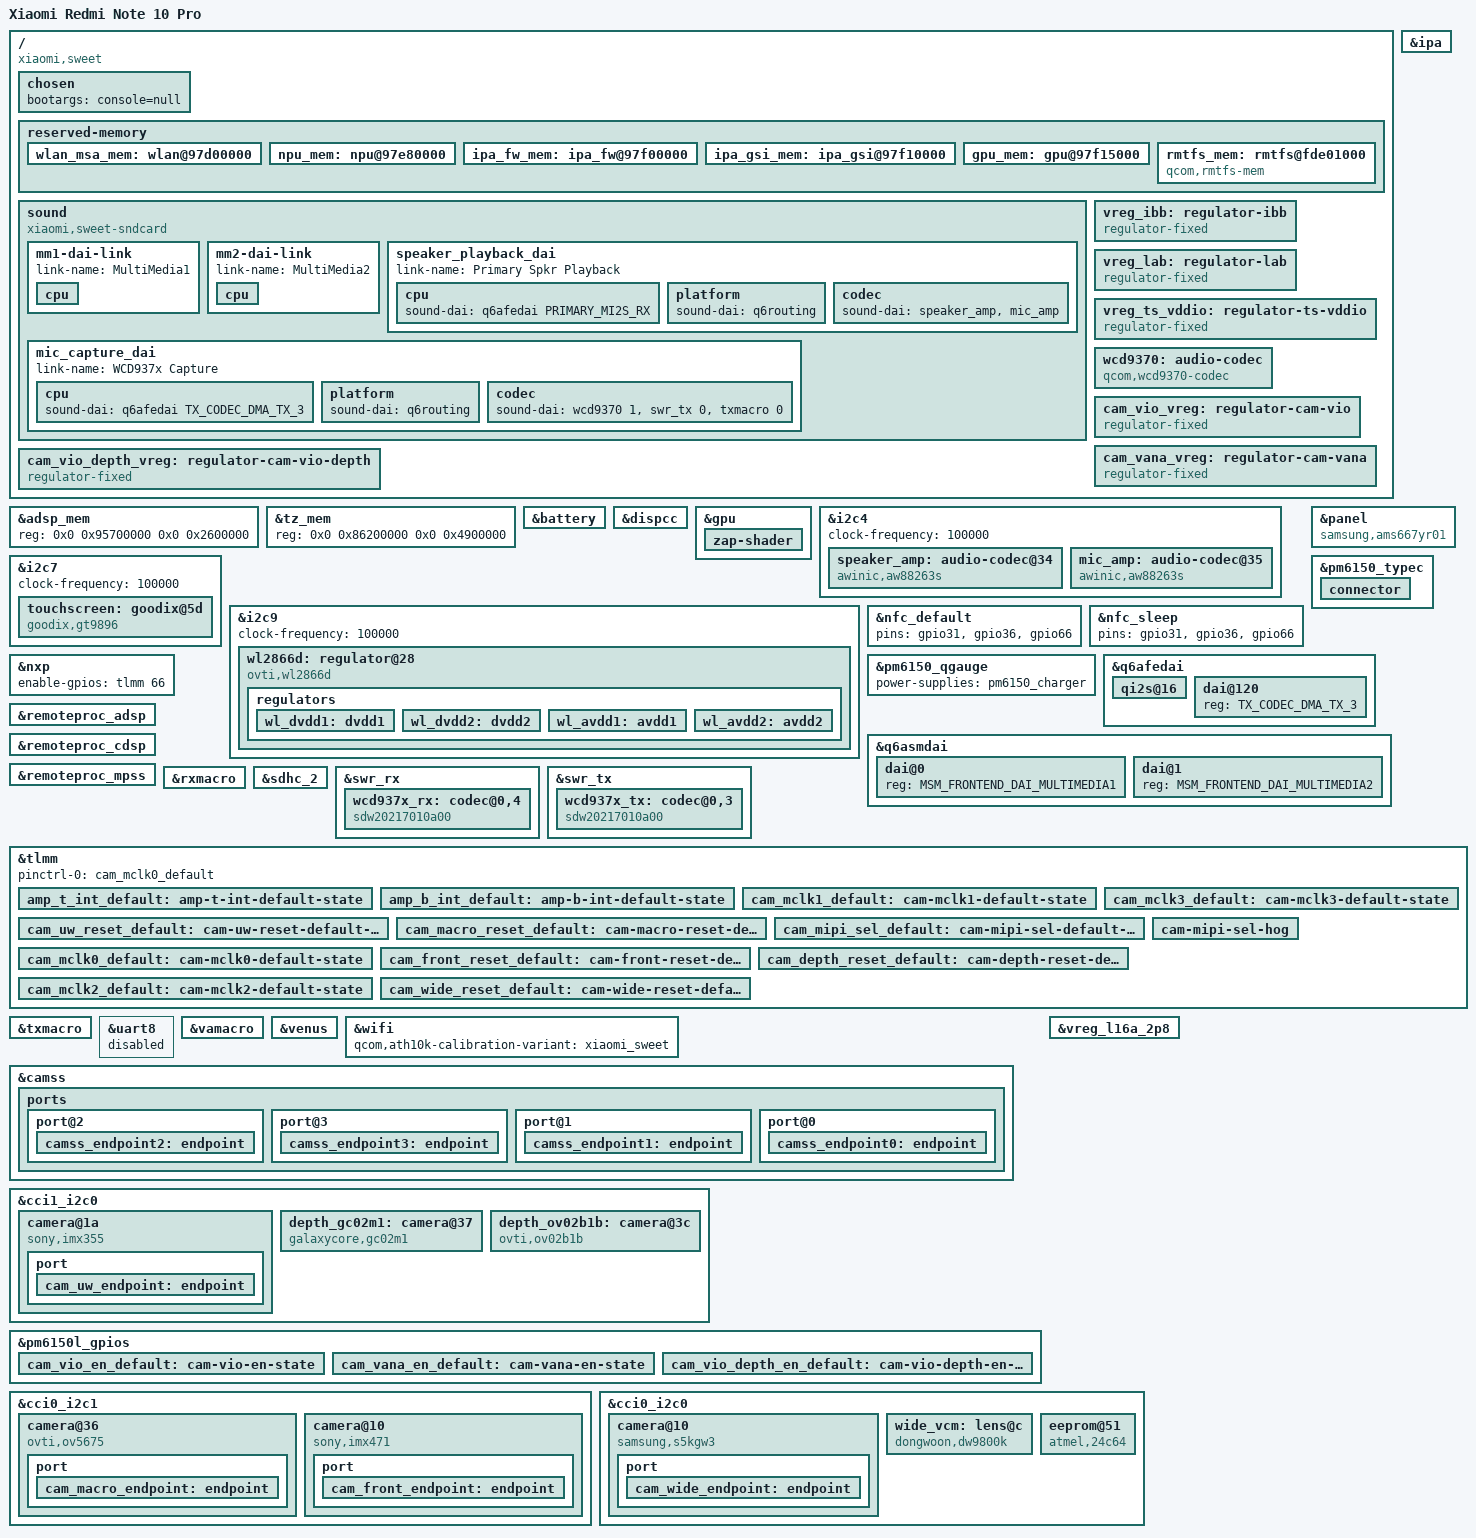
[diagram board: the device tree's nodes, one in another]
// SPDX-License-Identifier: BSD-3-Clause
/*
 * Copyright (c) 2024, Danila Tikhonov <danila@jiaxyga.com>
 * Copyright (c) 2024, Kali Prasad <kprasadvnsi@protonmail.com>
 * Copyright (c) 2024, Salvatore Stella <salvatore.stella@univaq.it>
 */

/dts-v1/;

#include "sm7150-xiaomi-common.dtsi"

/delete-node/ &wlan_msa_mem;
/delete-node/ &npu_mem;
/delete-node/ &ipa_fw_mem;
/delete-node/ &ipa_gsi_mem;
/delete-node/ &gpu_mem;

&adsp_mem {
	reg = <0x0 0x95700000 0x0 0x2600000>;
};

&tz_mem {
	reg = <0x0 0x86200000 0x0 0x4900000>;
};

/ {
	model = "Xiaomi Redmi Note 10 Pro";
	compatible = "xiaomi,sweet", "qcom,sm7150";

	qcom,board-id = <46 0>;

	chosen {
		/*
		 * Serial engine with the debug UART operates in SPI mode on sweet
		 * So disable console and remove stdout-path
		 */
		/delete-property/ stdout-path;
		bootargs = "console=null";
	};

	reserved-memory {
		wlan_msa_mem: wlan@97d00000 {
			reg = <0x0 0x97d00000 0x0 0x180000>;
			no-map;
		};

		npu_mem: npu@97e80000 {
			reg = <0x0 0x97e80000 0x0 0x80000>;
			no-map;
		};

		ipa_fw_mem: ipa_fw@97f00000 {
			reg = <0x0 0x97f00000 0x0 0x10000>;
			no-map;
		};

		ipa_gsi_mem: ipa_gsi@97f10000 {
			reg = <0x0 0x97f10000 0x0 0x5000>;
			no-map;
		};

		gpu_mem: gpu@97f15000 {
			reg = <0x0 0x97f15000 0x0 0x2000>;
			no-map;
		};

		rmtfs_mem: rmtfs@fde01000 {
			compatible = "qcom,rmtfs-mem";
			reg = <0 0xfde01000 0 0x200000>;
			no-map;

			qcom,client-id = <1>;
			qcom,vmid = <QCOM_SCM_VMID_MSS_MSA>;
		};
	};

	sound {
		compatible = "xiaomi,sweet-sndcard";
		pinctrl-0 = <&pri_mi2s_active &pri_mi2s_ws_active>;
		pinctrl-names = "default";
		model = "Redmi Note 10 Pro";
		widgets = "Speaker", "Speaker Spk",
			  "Speaker", "Microphone Spk";
		audio-routing = "Speaker Spk", "Speaker DAC Output",
				"Microphone Spk", "Microphone DAC Output",
				"Speaker AIF_RX", "PRI_MI2S_RX",
				"Microphone AIF_RX", "PRI_MI2S_RX",
				"AMIC1", "MIC BIAS1",
				"AMIC2", "MIC BIAS2",
				"AMIC3", "MIC BIAS3",
				"TX SWR_ADC0", "ADC1_OUTPUT";

		mm1-dai-link {
			link-name = "MultiMedia1";
			cpu {
				sound-dai = <&q6asmdai MSM_FRONTEND_DAI_MULTIMEDIA1>;
			};
		};

		mm2-dai-link {
			link-name = "MultiMedia2";
			cpu {
				sound-dai = <&q6asmdai MSM_FRONTEND_DAI_MULTIMEDIA2>;
			};
		};

		speaker_playback_dai {
			link-name = "Primary Spkr Playback";
			cpu {
				sound-dai = <&q6afedai PRIMARY_MI2S_RX>;
			};

			platform {
				sound-dai = <&q6routing>;
			};

			codec {
				sound-dai = <&speaker_amp>, <&mic_amp>;
			};
		};

		mic_capture_dai {
			link-name = "WCD937x Capture";
			cpu {
				sound-dai = <&q6afedai TX_CODEC_DMA_TX_3>;
			};

			platform {
				sound-dai = <&q6routing>;
			};

			codec {
				sound-dai = <&wcd9370 1>, <&swr_tx 0>, <&txmacro 0>;
			};
		};
	};

	vreg_ibb: regulator-ibb {
		compatible = "regulator-fixed";
		regulator-name = "ibb";
		regulator-min-microvolt = <6000000>;
		regulator-max-microvolt = <6000000>;
	};

	vreg_lab: regulator-lab {
		compatible = "regulator-fixed";
		regulator-name = "lab";
		regulator-min-microvolt = <6000000>;
		regulator-max-microvolt = <6000000>;
	};

	vreg_ts_vddio: regulator-ts-vddio {
		compatible = "regulator-fixed";
		regulator-name = "vreg_ts_vddio";
		regulator-min-microvolt = <1800000>;
		regulator-max-microvolt = <1800000>;
		gpio = <&tlmm 90 GPIO_ACTIVE_HIGH>;
		enable-active-high;
		regulator-boot-on;
		startup-delay-us = <4000>;
	};

	wcd9370: audio-codec {
		compatible = "qcom,wcd9370-codec";
		pinctrl-0 = <&wcd9375_reset_active>;
		pinctrl-names = "default";

		reset-gpios = <&lpass_tlmm 6 GPIO_ACTIVE_LOW>;

		vdd-buck-supply = <&vreg_l15a_1p8>;
		vdd-rxtx-supply = <&vreg_l10a_1p8>;
		vdd-px-supply = <&vreg_l10a_1p8>;
		vdd-mic-bias-supply = <&vreg_bob>;

		qcom,micbias1-microvolt = <2750000>;
		qcom,micbias2-microvolt = <2750000>;
		qcom,micbias3-microvolt = <2750000>;
		qcom,mbhc-buttons-vthreshold-microvolt = <75000 150000 237000 500000
							  500000 500000 500000 500000>;

		qcom,rx-device = <&wcd937x_rx>;
		qcom,tx-device = <&wcd937x_tx>;

		#sound-dai-cells = <1>;
	};
};

&battery {
	charge-full-design-microamp-hours = <5020000>;
	/* Also the DCP input current limit of the charger, AICL backs off on weak adapters */
	constant-charge-current-max-microamp = <2000000>;
	/* K6 Sunwoda 5020 mAh profile from the downstream qpnp-qg battery data, 25 degC */
	factory-internal-resistance-micro-ohms = <200000>;
	ocv-capacity-celsius = <25>;
	ocv-capacity-table-0 = <4433500 100>, <4416800 98>, <4399000 96>, <4380200 94>,
		<4360400 92>, <4339300 90>, <4316400 88>, <4292500 86>,
		<4268400 84>, <4243800 82>, <4219400 80>, <4195100 78>,
		<4171300 76>, <4148000 74>, <4125300 72>, <4103300 70>,
		<4081900 68>, <4061100 66>, <4041400 64>, <4023000 62>,
		<4002100 60>, <3973100 58>, <3943500 56>, <3924400 54>,
		<3910600 52>, <3898200 50>, <3886500 48>, <3875600 46>,
		<3865200 44>, <3855100 42>, <3845900 40>, <3837700 38>,
		<3830200 36>, <3823400 34>, <3817200 32>, <3811500 30>,
		<3806300 28>, <3801100 26>, <3793700 24>, <3783300 22>,
		<3771500 20>, <3758600 18>, <3744500 16>, <3728000 14>,
		<3715300 12>, <3707800 10>, <3705700 9>, <3704200 8>,
		<3701200 7>, <3688500 6>, <3652500 5>, <3604600 4>,
		<3542800 3>, <3458300 2>, <3325600 1>, <3000000 0>;
};

&dispcc {
	status = "okay";
};

&gpu {
	zap-shader {
		firmware-name = "qcom/sm7150/xiaomi/sweet/a615_zap.mbn";
	};
};

&i2c4 {
	clock-frequency = <100000>;
	status = "okay";

	/* Speaker */
        speaker_amp: audio-codec@34 {
		compatible = "awinic,aw88263s";
		reg = <0x34>;

		reset-gpios = <&tlmm 64 GPIO_ACTIVE_HIGH>;
		irq-gpio = <&tlmm 93 GPIO_ACTIVE_HIGH>;

		pinctrl-names = "default";
		pinctrl-0 = <&amp_t_int_default>;

		awinic,audio-channel = <0>;

		sound-name-prefix = "Speaker";
		#sound-dai-cells = <0>;
        };

	/* Microphone */
	mic_amp: audio-codec@35 {
		compatible = "awinic,aw88263s";
		reg = <0x35>;

		reset-gpios = <&tlmm 72 GPIO_ACTIVE_HIGH>;
		irq-gpio = <&tlmm 56 GPIO_ACTIVE_HIGH>;

		pinctrl-names = "default";
		pinctrl-0 = <&amp_b_int_default>;

		awinic,audio-channel = <1>;

		sound-name-prefix = "Microphone";
		#sound-dai-cells = <0>;
        };
};

&i2c7 {
	clock-frequency = <100000>;
	status = "okay";

	touchscreen: goodix@5d {
		compatible = "goodix,gt9896";
		reg = <0x5d>;
		interrupts-extended = <&tlmm 9 IRQ_TYPE_LEVEL_LOW>;
		reset-gpios = <&tlmm 8 GPIO_ACTIVE_LOW>;
		avdd-supply = <&vreg_l11c_3p3>;
		vddio-supply = <&vreg_ts_vddio>;
		panel = <&panel>;
		touchscreen-size-x = <1080>;
		touchscreen-size-y = <2400>;
	};
};

&i2c9 {
	clock-frequency = <100000>;
	status = "okay";

	wl2866d: regulator@28 {
		compatible = "ovti,wl2866d";
		reg = <0x28>;

		enable-gpios = <&tlmm 30 GPIO_ACTIVE_HIGH>;
		vin1-supply = <&vreg_s8c_1p35>;
		vin2-supply = <&vreg_bob>;

		regulators {
			wl_dvdd1: dvdd1 {
				regulator-name = "wl_dvdd1";
				regulator-min-microvolt = <1200000>;
				regulator-max-microvolt = <1200000>;
			};

			wl_dvdd2: dvdd2 {
				regulator-name = "wl_dvdd2";
				regulator-min-microvolt = <1050000>;
				regulator-max-microvolt = <1050000>;
			};

			wl_avdd1: avdd1 {
				regulator-name = "wl_avdd1";
				regulator-min-microvolt = <2800000>;
				regulator-max-microvolt = <2800000>;
			};

			wl_avdd2: avdd2 {
				regulator-name = "wl_avdd2";
				regulator-min-microvolt = <2700000>;
				regulator-max-microvolt = <2700000>;
			};
		};
	};

	/* lionsemi,ln8000 (charger) @ 51 */
	/* awinic,aw8624 (haptics) @ 5a */
	/* ti,bq2597x (charger) @ 66 */
};

&ipa {
	firmware-name = "qcom/sm7150/xiaomi/sweet/ipa_fws.mbn";
};

&nfc_default {
	pins = "gpio31", "gpio36", "gpio66";
};

&nfc_sleep {
	pins = "gpio31", "gpio36", "gpio66";
};

&nxp {
	enable-gpios = <&tlmm 66 GPIO_ACTIVE_HIGH>;
};

&panel {
	compatible = "samsung,ams667yr01";

	vsn-supply = <&vreg_ibb>;
	vsp-supply = <&vreg_lab>;
};

&pm6150_qgauge {
	power-supplies = <&pm6150_charger>;
};

&pm6150_typec {
	connector {
		op-sink-microwatt = <15000000>;
		power-role = "dual";

		sink-pdos = <PDO_FIXED(5000, 3000, PDO_FIXED_DUAL_ROLE |
			     PDO_FIXED_USB_COMM | PDO_FIXED_DATA_SWAP)>;
	};
};

&q6afedai {
	qi2s@16 {
		reg = <PRIMARY_MI2S_RX>;
		qcom,sd-lines = <0>;
	};

	dai@120 {
		reg = <TX_CODEC_DMA_TX_3>;
	};
};

&q6asmdai {
	dai@0 {
		reg = <MSM_FRONTEND_DAI_MULTIMEDIA1>;
	};

	dai@1 {
		reg = <MSM_FRONTEND_DAI_MULTIMEDIA2>;
	};
};

&remoteproc_adsp {
	firmware-name = "qcom/sm7150/xiaomi/sweet/adsp.mbn";
};

&remoteproc_cdsp {
	firmware-name = "qcom/sm7150/xiaomi/sweet/cdsp.mbn";
};

&remoteproc_mpss {
	firmware-name = "qcom/sm7150/xiaomi/sweet/modem.mbn";
};

&rxmacro {
	status = "okay";
};

&sdhc_2 {
	status = "okay";
};

&swr_rx {
	status = "okay";

	wcd937x_rx: codec@0,4 {
		compatible = "sdw20217010a00";
		reg = <0 4>;
		qcom,rx-port-mapping = <1 2 3 4 5>;
		qcom,rx-channel-mapping = /bits/ 8 <1 2 1 1 2 1 1 2>;
		#sound-dai-cells = <1>;
	};
};

&swr_tx {
	status = "okay";

	wcd937x_tx: codec@0,3 {
		compatible = "sdw20217010a00";
		reg = <0 3>;
		qcom,tx-port-mapping = <2 3 4 5>;
		qcom,tx-channel-mapping = /bits/ 8 <1 1 2 1 2 3 3 4 1 2 3 4>;
		#sound-dai-cells = <1>;
	};
};

&tlmm {
	amp_t_int_default: amp-t-int-default-state {
		pins = "gpio93";
		function = "gpio";
		drive-strength = <2>;
		bias-pull-up;
		input-enable;
	};

	amp_b_int_default: amp-b-int-default-state {
		pins = "gpio56";
		function = "gpio";
		drive-strength = <2>;
		bias-pull-up;
		input-enable;
	};
};

&txmacro {
	status = "okay";
};

&uart8 {
	status = "disabled";
};

&vamacro {
	status = "okay";
};

&venus {
	firmware-name = "qcom/sm7150/xiaomi/sweet/venus.mbn";
};

&wifi {
	qcom,ath10k-calibration-variant = "xiaomi_sweet";
};

/ {
	/* DOVDD 1.8 V for the cameras: pm6150l gpio4 */
	cam_vio_vreg: regulator-cam-vio {
		compatible = "regulator-fixed";
		regulator-name = "cam_vio";
		regulator-min-microvolt = <1800000>;
		regulator-max-microvolt = <1800000>;
		regulator-enable-ramp-delay = <100>;
		gpio = <&pm6150l_gpios 4 GPIO_ACTIVE_HIGH>;
		enable-active-high;
		vin-supply = <&vreg_s5a_2p0>;
		pinctrl-0 = <&cam_vio_en_default>;
		pinctrl-names = "default";
	};
};

&camss {
	ports {
		port@2 {
			camss_endpoint2: endpoint {
				data-lanes = <0 1 2 3>;
				remote-endpoint = <&cam_uw_endpoint>;
			};
		};
	};
};

/* 8 MP ultra-wide camera */
&cci1_i2c0 {
	camera@1a {
		compatible = "sony,imx355";
		reg = <0x1a>;

		clocks = <&camcc CAMCC_MCLK1_CLK>;
		assigned-clocks = <&camcc CAMCC_MCLK1_CLK>;
		assigned-clock-rates = <19200000>;

		reset-gpios = <&tlmm 25 GPIO_ACTIVE_LOW>;

		avdd-supply = <&wl_avdd2>;
		dvdd-supply = <&wl_dvdd1>;
		dovdd-supply = <&cam_vio_vreg>;

		pinctrl-0 = <&cam_mclk1_default &cam_uw_reset_default>;
		pinctrl-names = "default";

		orientation = <1>;
		rotation = <90>;

		port {
			cam_uw_endpoint: endpoint {
				data-lanes = <1 2 3 4>;
				link-frequencies = /bits/ 64 <360000000>;
				remote-endpoint = <&camss_endpoint2>;
			};
		};
	};
};

&pm6150l_gpios {
	cam_vio_en_default: cam-vio-en-state {
		pins = "gpio4";
		function = PMIC_GPIO_FUNC_NORMAL;
		power-source = <0>;
	};
};

&tlmm {
	cam_mclk1_default: cam-mclk1-default-state {
		pins = "gpio14";
		function = "cam_mclk";
		drive-strength = <4>;
		bias-disable;
	};

	cam_uw_reset_default: cam-uw-reset-default-state {
		pins = "gpio25";
		function = "gpio";
		drive-strength = <2>;
		bias-disable;
	};
};

/ {
	/*
	 * AVDD 2.8 V for the macro (OV5675) and depth cameras: pm6150l gpio11,
	 * vin BOB (downstream camera_d_vdda_regulator, "cam_vana")
	 */
	cam_vana_vreg: regulator-cam-vana {
		compatible = "regulator-fixed";
		regulator-name = "cam_vana";
		regulator-min-microvolt = <2800000>;
		regulator-max-microvolt = <2800000>;
		regulator-enable-ramp-delay = <100>;
		gpio = <&pm6150l_gpios 11 GPIO_ACTIVE_HIGH>;
		enable-active-high;
		vin-supply = <&vreg_bob>;
		pinctrl-0 = <&cam_vana_en_default>;
		pinctrl-names = "default";
	};
};

&camss {
	ports {
		port@3 {
			camss_endpoint3: endpoint {
				data-lanes = <0 1>;
				bus-type = <4>; /* MEDIA_BUS_TYPE_CSI2_DPHY */
				remote-endpoint = <&cam_macro_endpoint>;
			};
		};
	};
};

/* 5 MP macro camera, shares CSIPHY3 with the depth camera via a MIPI switch */
&cci0_i2c1 {
	camera@36 {
		compatible = "ovti,ov5675";
		reg = <0x36>;

		clocks = <&camcc CAMCC_MCLK3_CLK>;
		assigned-clocks = <&camcc CAMCC_MCLK3_CLK>;
		assigned-clock-rates = <19200000>;

		reset-gpios = <&tlmm 24 GPIO_ACTIVE_LOW>;

		avdd-supply = <&cam_vana_vreg>;
		dvdd-supply = <&wl_dvdd1>;
		dovdd-supply = <&cam_vio_vreg>;

		pinctrl-0 = <&cam_mclk3_default &cam_macro_reset_default
			     &cam_mipi_sel_default>;
		pinctrl-names = "default";

		orientation = <1>;
		rotation = <90>;

		port {
			cam_macro_endpoint: endpoint {
				data-lanes = <1 2>;
				link-frequencies = /bits/ 64 <450000000>;
				remote-endpoint = <&camss_endpoint3>;
			};
		};
	};
};

&pm6150l_gpios {
	cam_vana_en_default: cam-vana-en-state {
		pins = "gpio11";
		function = PMIC_GPIO_FUNC_NORMAL;
		power-source = <0>;
	};
};

&tlmm {
	cam_mclk3_default: cam-mclk3-default-state {
		pins = "gpio16";
		function = "cam_mclk";
		drive-strength = <4>;
		bias-disable;
	};

	cam_macro_reset_default: cam-macro-reset-default-state {
		pins = "gpio24";
		function = "gpio";
		drive-strength = <2>;
		bias-disable;
	};

	cam_mipi_sel_default: cam-mipi-sel-default-state {
		pins = "gpio88";
		function = "gpio";
		drive-strength = <2>;
		bias-disable;
	};

	/*
	 * MIPI switch select for CSIPHY3 (downstream gpio-custom1 = tlmm 88,
	 * CamX power-up sequence drives it HIGH for the macro, LOW for depth).
	 * No mainline driver for the depth sensor, so pin it to the macro.
	 */
	cam-mipi-sel-hog {
		gpio-hog;
		gpios = <88 GPIO_ACTIVE_HIGH>;
		output-high;
		line-name = "cam-mipi-sel-macro";
	};
};

&camss {
	ports {
		port@1 {
			camss_endpoint1: endpoint {
				data-lanes = <0 1 2 3>;
				remote-endpoint = <&cam_front_endpoint>;
			};
		};
	};
};

/* 16 MP front camera, Sony IMX471 */
&cci0_i2c1 {
	camera@10 {
		compatible = "sony,imx471";
		reg = <0x10>;

		clocks = <&camcc CAMCC_MCLK0_CLK>;
		assigned-clocks = <&camcc CAMCC_MCLK0_CLK>;
		assigned-clock-rates = <19200000>;

		reset-gpios = <&tlmm 23 GPIO_ACTIVE_LOW>;

		avdd-supply = <&cam_vana_vreg>;
		dvdd-supply = <&wl_dvdd2>;
		dovdd-supply = <&cam_vio_vreg>;

		/*
		 * MCLK0 (gpio13) is shared with the depth camera on cci1_i2c0;
		 * cam_mclk0_default is applied as a tlmm hog (see &tlmm below).
		 */
		pinctrl-0 = <&cam_front_reset_default>;
		pinctrl-names = "default";

		orientation = <0>;
		/*
		 * Android reports roll 270 with the sensor read out H+V flipped
		 * (init table 0x0101 = 0x03); this driver defaults to no flip,
		 * so the mounting rotation is 270 - 180 = 90.
		 */
		rotation = <90>;

		port {
			cam_front_endpoint: endpoint {
				data-lanes = <1 2 3 4>;
				link-frequencies = /bits/ 64 <164800000>;
				remote-endpoint = <&camss_endpoint1>;
			};
		};
	};
};

&tlmm {
	cam_mclk0_default: cam-mclk0-default-state {
		pins = "gpio13";
		function = "cam_mclk";
		drive-strength = <4>;
		bias-disable;
	};

	cam_front_reset_default: cam-front-reset-default-state {
		pins = "gpio23";
		function = "gpio";
		drive-strength = <2>;
		bias-disable;
	};
};

/ {
	/*
	 * DOVDD 1.8 V for the depth camera: pm6150l gpio8 (downstream
	 * camera_vddio_depth_regulator). Chained to cam_vio (pm6150l gpio4,
	 * downstream cam_v_custom1 of the depth node: I/O rail of the
	 * depth/macro MIPI switch), so that rail is on whenever depth is.
	 */
	cam_vio_depth_vreg: regulator-cam-vio-depth {
		compatible = "regulator-fixed";
		regulator-name = "cam_vio_depth";
		regulator-min-microvolt = <1800000>;
		regulator-max-microvolt = <1800000>;
		regulator-enable-ramp-delay = <100>;
		gpio = <&pm6150l_gpios 8 GPIO_ACTIVE_HIGH>;
		enable-active-high;
		vin-supply = <&cam_vio_vreg>;
		pinctrl-0 = <&cam_vio_depth_en_default>;
		pinctrl-names = "default";
	};
};

/*
 * 2 MP depth camera, dual-sourced: GalaxyCore GC02M1 (Sunny module, 0x37)
 * or OmniVision OV02B1B (Ofilm module, 0x3c). Both share reset tlmm 21 and
 * MCLK0 (tlmm 13, also the front camera's MCLK). Probe-only: no port yet,
 * the driver of the fitted sensor logs "... detected (chip id ...)" and
 * then fails with "no endpoint (probe-only mode)"; the other one fails
 * with "chip id mismatch" / i2c error or -EBUSY on the shared reset GPIO.
 */
&cci1_i2c0 {
	depth_gc02m1: camera@37 {
		compatible = "galaxycore,gc02m1";
		reg = <0x37>;

		clocks = <&camcc CAMCC_MCLK0_CLK>;
		assigned-clocks = <&camcc CAMCC_MCLK0_CLK>;
		assigned-clock-rates = <19200000>;

		reset-gpios = <&tlmm 21 GPIO_ACTIVE_LOW>;

		dovdd-supply = <&cam_vio_depth_vreg>;
		avdd-supply = <&cam_vana_vreg>;

		pinctrl-0 = <&cam_depth_reset_default>;
		pinctrl-names = "default";

		orientation = <1>;
		rotation = <90>;
	};

	depth_ov02b1b: camera@3c {
		compatible = "ovti,ov02b1b";
		reg = <0x3c>;

		clocks = <&camcc CAMCC_MCLK0_CLK>;
		assigned-clocks = <&camcc CAMCC_MCLK0_CLK>;
		assigned-clock-rates = <19200000>;

		reset-gpios = <&tlmm 21 GPIO_ACTIVE_LOW>;

		dovdd-supply = <&cam_vio_depth_vreg>;
		avdd-supply = <&cam_vana_vreg>;

		orientation = <1>;
		rotation = <90>;
	};
};

&pm6150l_gpios {
	cam_vio_depth_en_default: cam-vio-depth-en-state {
		pins = "gpio8";
		function = PMIC_GPIO_FUNC_NORMAL;
		power-source = <0>;
	};
};

&tlmm {
	/*
	 * MCLK0 (gpio13, cam_mclk0_default) feeds both the front camera
	 * (cci0_i2c1) and the depth camera (cci1_i2c0). A pin can only be muxed
	 * by one device, so mux it here as a tlmm pinctrl hog instead of in a
	 * sensor node; both sensors reference <&camcc CAMCC_MCLK0_CLK>, which
	 * is refcounted.
	 */
	pinctrl-0 = <&cam_mclk0_default>;
	pinctrl-names = "default";

	cam_depth_reset_default: cam-depth-reset-default-state {
		pins = "gpio21";
		function = "gpio";
		drive-strength = <2>;
		bias-disable;
	};
};

/*
 * L16A: on sweet it only feeds the wide camera VCM (downstream cam_vaf,
 * 2.8 V, pm6150 L16 range 2.424-2.976 V). The common dtsi pins it at 1.8 V.
 */
&vreg_l16a_2p8 {
	regulator-min-microvolt = <2800000>;
	regulator-max-microvolt = <2800000>;
};

&camss {
	ports {
		port@0 {
			camss_endpoint0: endpoint {
				data-lanes = <0 1 2 3>;
				remote-endpoint = <&cam_wide_endpoint>;
			};
		};
	};
};

/*
 * 64 MP wide camera, Samsung S5KGW3 (Redmi Note 10 Pro India, M2101K6P).
 * The Pro Max (M2101K6I) and the global Pro (M2101K6G) carry a 108 MP
 * S5KHM2 at the same address (chip id 0x1ad2), which needs MIPI C-PHY.
 */
&cci0_i2c0 {
	camera@10 {
		compatible = "samsung,s5kgw3";
		reg = <0x10>;

		clocks = <&camcc CAMCC_MCLK2_CLK>;
		assigned-clocks = <&camcc CAMCC_MCLK2_CLK>;
		assigned-clock-rates = <19200000>;

		reset-gpios = <&tlmm 26 GPIO_ACTIVE_LOW>;

		vddio-supply = <&cam_vio_vreg>;
		/* downstream cam_vdig = L6A (1.05 V requested, L6A min is 1.096 V) */
		vddd-supply = <&vreg_l6a_1p2>;
		vdda-supply = <&wl_avdd1>;

		pinctrl-0 = <&cam_mclk2_default &cam_wide_reset_default>;
		pinctrl-names = "default";

		lens-focus = <&wide_vcm>;

		orientation = <1>;
		rotation = <90>;

		port {
			cam_wide_endpoint: endpoint {
				data-lanes = <1 2 3 4>;
				link-frequencies = /bits/ 64 <835200000>;
				remote-endpoint = <&camss_endpoint0>;
			};
		};
	};

	/*
	 * Dongwoon DW9800V VCM (vendor actuatorName "dw9800v"); the vendor init
	 * (0x02 = 0x02 ringing, 0x06 = 0x80 SAC mode 2, 0x07 = 0x6a, 10-bit
	 * DAC at 0x03/0x04) matches the DW9800K support of the dw9719 driver.
	 * 0x0c is the usual DW98xx address, not confirmed from the blobs.
	 */
	wide_vcm: lens@c {
		compatible = "dongwoon,dw9800k";
		reg = <0x0c>;
		vdd-supply = <&vreg_l16a_2p8>;
		dongwoon,sac-mode = <2>;
		dongwoon,vcm-prescale = <0x6a>;
	};

	/* module OTP EEPROM (vendor EEPROM slave 0xa2), read-only */
	eeprom@51 {
		compatible = "atmel,24c64";
		reg = <0x51>;
		vcc-supply = <&cam_vio_vreg>;
		read-only;
	};
};

&tlmm {
	cam_mclk2_default: cam-mclk2-default-state {
		pins = "gpio15";
		function = "cam_mclk";
		drive-strength = <4>;
		bias-disable;
	};

	cam_wide_reset_default: cam-wide-reset-default-state {
		pins = "gpio26";
		function = "gpio";
		drive-strength = <2>;
		bias-disable;
	};
};
